# AC690N register map
Vendor: JieLi; Series: BR17; File version: 1.0
JieLi AC690N Bluetooth Audio series (BR17)
CPU: PI32 r1, little endian, no MPU, no FPU, 2 interrupt priority bits, 64 interrupts
Registers are 32-bit, read-write, reset 0x0 unless marked. A register's access mark holds for its fields unless they carry their own. Offsets are from the block's base; lines under a group give offsets from that group; [hi:lo] are bit positions; {n}, {i} and the like mark numbered series; 'fields as' and 'values as' point back to an identical list; <NAME> marks a mode.

## Memory map
0x00060000 SYSCFG size 0x100 — System configuration and like
0x00060100 PORTA size 0x20 — GPIO bank A
0x00060120 PORTB size 0x20 — GPIO bank B
0x00060140 PORTC size 0x20 — GPIO bank C
0x00060160 PORTD size 0x20 — GPIO bank D
0x00060200 TIMER0 size 0x10 — 16-bit timer
0x00060210 TIMER1 size 0x10
0x00060220 TIMER2 size 0x10
0x00060230 TIMER3 size 0x10
0x00060300 UART0 size 0x24 — UART interface
0x00060324 UART1 size 0x24
0x00060348 UART2 size 0xC — UART interface (cut-down variant)
0x00060400 SPI0 size 0x14 — Serial Peripheral Interface controller
0x00060414 SPI1 size 0x14
0x00060428 SPI2 size 0x14
0x00060500 PAP size 0x18 — Parralel Active Port
0x00060600 SD0 size 0x14 — SD/MMC host
0x00060614 SD1 size 0x14
0x00060900 LSMISC size 0x100 — Misc stuff on lowspeed bus
0x00060A00 AUDIO size 0x100 — Audio codec
0x00060B00 ALNK size 0x20 — Serial audio link (I2S)
0x00060C00 NFC size 0x20 — ISO-14993 NFC
0x00060D00 USB size 0x100 — Full-speed dual role USB controller
0x00060E00 CRC size 0x8 — CRC16-CCITT
0x00060F00 RAND size 0x8 — 64-bit random number generator
0x00061000 ADC size 0x8 — Generic 10-bit ADC
0x00061100 PLCNT size 0x8 — Pulse counter
0x00061200 PD size 0x8 — Power down control
0x00061300 CTM size 0xC — Charge time measurement unit
0x00061400 SPDET size 0x100 — Speed detector thing
0x00061C00 WLA size 0x100 — WL (Bluetooth) analog control
0x00061D00 FMA size 0x100 — FM receiver analog control
0x00070000 CPU size 0x100 — CPU or like peripherals
0x00070100 DEBUG size 0x100 — Debug-ish stuff
0x00070200 SFC size 0x10 — Serial flash controller
0x00070300 ENC size 0x14 — Enc-rypter
0x00070500 AES size 0x2C — AES engine
0x00070600 FFT size 0x10 — Fast Fourier transform
0x00070700 EQ size 0x14 — Equalizer
0x00070800 SRC size 0x24 — Sampling rate converter
0x00070900 FMRX size 0x100 — FM receiver (digital part)
0x00070A00 MCPWM size 0x100 — Motor control PWM

## Interrupts
2 TIM0 (TIMER0) — Timer 0 interrupt
3 TIM1 (TIMER1) — Timer 1 interrupt
4 TIM2 (TIMER2) — Timer 2 interrupt
5 TIM3 (TIMER3) — Timer 3 interrupt
12 SPI0 — SPI0 interrupt
13 SPI1 — SPI1 interrupt
14 SD0 — SD0 interrupt
15 SD1 — SD1 interrupt
16 UART0 — UART0 interrupt
17 UART1 — UART1 interrupt
18 UART2 — UART2 interrupt
19 PAP — PAP interrupt

## PORTA — GPIO bank A
Base 0x00060100
Same registers: PORTB 0x00060120, PORTC 0x00060140, PORTD 0x00060160
0x00 OUT 16-bit — Output level register
0x04 IN 16-bit — Input state register
0x08 DIR 16-bit — Direction control register
0x0C DIE 16-bit — Digital input enable register
0x10 PU 16-bit — Pullup enable register
0x14 PD 16-bit — Pulldown enable register
0x18 HD 16-bit — High drive current enable register

## TIMER0 — 16-bit timer
Base 0x00060200
Same registers: TIMER1 0x00060210, TIMER2 0x00060220, TIMER3 0x00060230
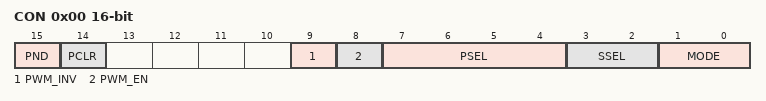
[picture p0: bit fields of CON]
0x00 CON 16-bit — Control register
  [15] PND ro — Interrupt pending bit
  [14] PCLR wo — Writing a '1' clears the pending interrupt
  [9] PWM_INV — PWM output inversion enable
  [8] PWM_EN — PWM output enable
  [7:4] PSEL — Timer clock prescaler
    0=div1 (Timer clock is divided by 1); 1=div4 (Timer clock is divided by 4); 2=div16 (Timer clock is divided by 16); 3=div64 (Timer clock is divided by 64); 4=div2 (Timer clock is divided by 4 (1*2)); 5=div8 (Timer clock is divided by 8 (4*2)); 6=div32 (Timer clock is divided by 32 (16*2)); 7=div128 (Timer clock is divided by 128 (64*2)); 8=div256 (Timer clock is divided by 256 (1*256)); 9=div1024 (Timer clock is divided by 1024 (4*256)); 10=div4096 (Timer clock is divided by 4096 (16*256)); 11=div16384 (Timer clock is divided by 16384 (64*256)); 12=div512 (Timer clock is divided by 512 (1*2*256)); 13=div2048 (Timer clock is divided by 2048 (4*2*256)); 14=div8192 (Timer clock is divided by 8192 (16*2*256)); 15=div32768 (Timer clock is divided by 32768 (64*2*256))
  [3:2] SSEL — Timer clock source selection
    0=busclk (Timer clocks from its bus clock); 1=extclk (Timer clocks from its external clock input 'TMR'); 2=oscclk (Timer clocks from the osc_clk clock signal, usually wired to bt_osc which is typically 24 MHz); 3=rcclk (Timer clocks from the rc_clk clock signal, which is around 250 kHz)
  [1:0] MODE — Timer operation mode
    0=disabled (Timer is disabled); 1=counting (Timer is counting); 2=capture_rising (Timer captures rising edge on its 'CAP' input); 3=capture_falling (Timer captures falling edge on its 'CAP' input)
0x04 CNT 16-bit — Counter register
  [15:0] CNT — This register holds the current value of the timer's counter.
0x08 PRD 16-bit — Period register
  [15:0] PRD — When the counter reaches the value in this register, the counter resets and an interrupt is generated.
0x0C PWM 16-bit — PWM duty cycle
  [15:0] PWM — When the counter reaches the value in this register, the PWM output will go high (or low), if it is enabled.
